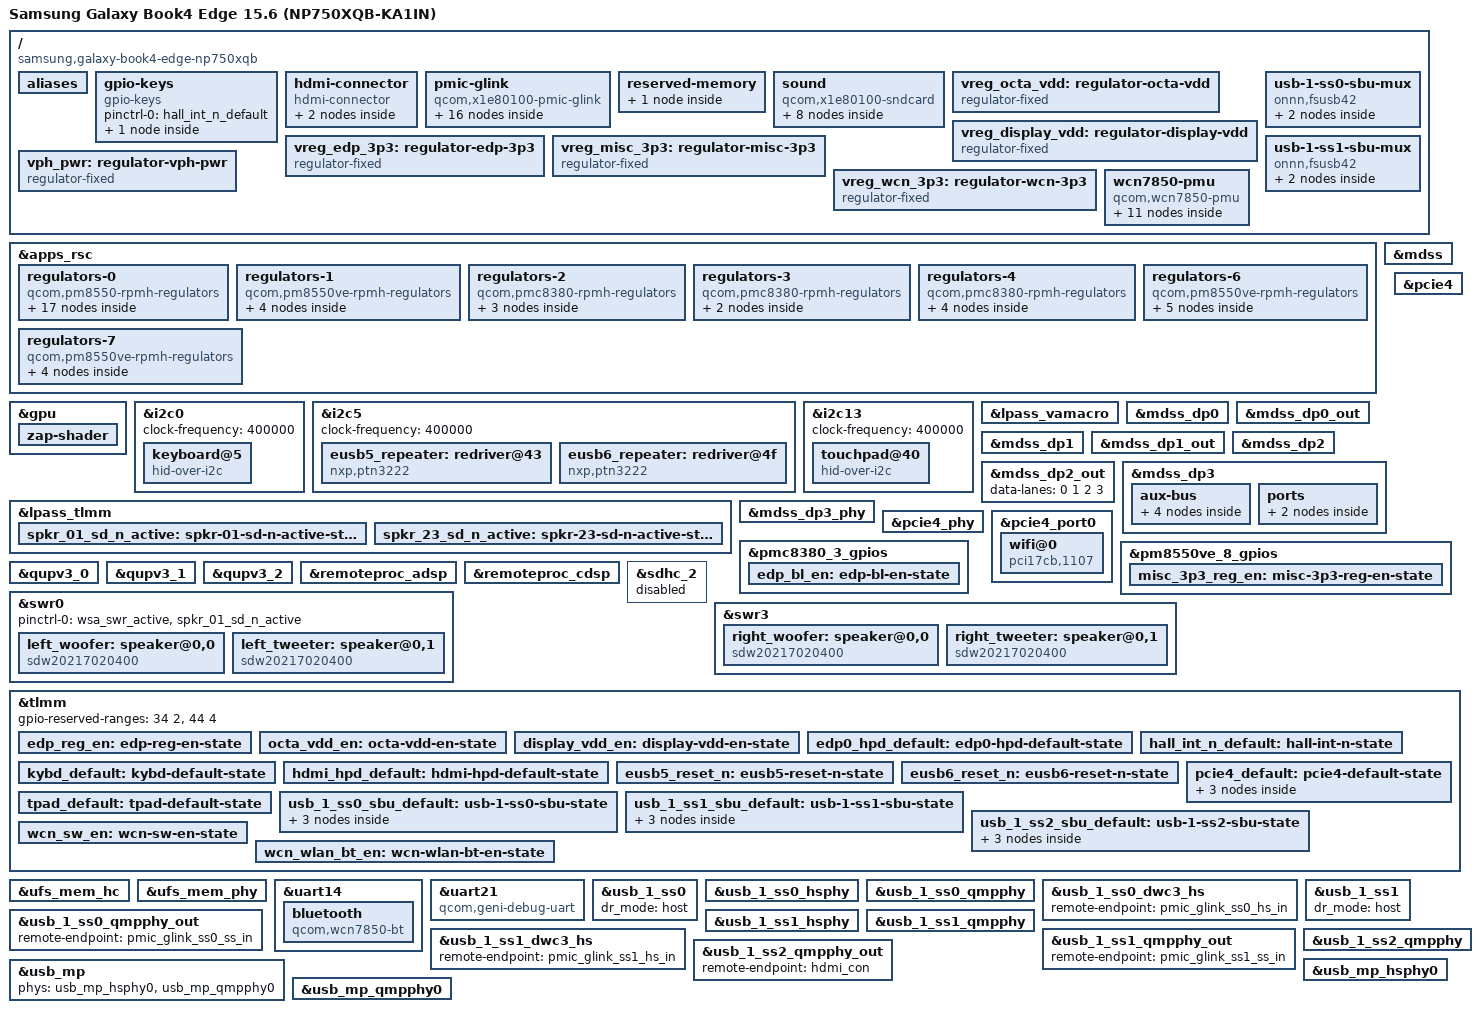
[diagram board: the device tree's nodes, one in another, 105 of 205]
// SPDX-License-Identifier: BSD-3-Clause
/*
 * Copyright (c) 2023 Qualcomm Innovation Center, Inc. All rights reserved.
 * Copyright (c) 2025 Kirill A. Korinsky <kirill@korins.ky>
 * Copyright (c) 2025 Valentin Manea <valentin.manea@mrs.ro>
 *
 * Rebased for the Samsung Galaxy Book4 Edge 15.6" (NP750XQB-KA1IN, India SKU),
 * which uses the Purwa die (X1P-26-100 marketing name) — the same silicon as
 * X1P-42-100 (purwa.dtsi) but clocked down 3.4GHz -> 3.0GHz, with 8 of 12 cores
 * fused (confirmed from MADT: 4 efficiency + 4 performance active, cluster 2
 * disabled). Board-level nodes below are carried over from the X1E80100 16"
 * Book4 Edge (zensanp/linux-book4-edge) since it's the same board family, and
 * adjusted against our own DSDT/EDID/Windows-PnP reverse engineering where the
 * two boards diverge (panel, keyboard, PMIC count, MicroSD, HDMI bridge, audio
 * codec). Nodes still needing verification are marked TODO.
 */

/dts-v1/;

#include <dt-bindings/gpio/gpio.h>
#include <dt-bindings/input/gpio-keys.h>
#include <dt-bindings/input/input.h>
#include <dt-bindings/pinctrl/qcom,pmic-gpio.h>
#include <dt-bindings/regulator/qcom,rpmh-regulator.h>

#include "purwa.dtsi"
#include "hamoa-pmics.dtsi"

/* Purwa is 5-PMIC (SIDS=SCP_PURWA); Hamoa/X1E is 6-PMIC.
 * purwa.dtsi should already omit pmc8380_6, but delete defensively
 * in case the included dtsi still carries it from the shared base.
 */
/delete-node/ &pmc8380_6;
/delete-node/ &pmc8380_6_thermal;

/ {
	model = "Samsung Galaxy Book4 Edge 15.6 (NP750XQB-KA1IN)";
	compatible = "samsung,galaxy-book4-edge-np750xqb", "qcom,x1p26100";
	chassis-type = "laptop";

	aliases {
		serial0 = &uart21;
		serial1 = &uart14;
	};

	/*
	 * TODO: NP750XQB uses a Samsung SAMM0851 custom WCD codec over
	 * SlimBus (per Windows PnP + DSDT), NOT the WCD9385 SoundWire codec
	 * this board template uses. No upstream driver/binding exists for
	 * SAMM0851 yet. Omitting the codec node (and its DAI links below)
	 * until that's reverse engineered further — audio will be silent
	 * until then.
	 */

	gpio-keys {
		compatible = "gpio-keys";

		pinctrl-0 = <&hall_int_n_default>;
		pinctrl-names = "default";

		switch-lid {
			gpios = <&tlmm 92 GPIO_ACTIVE_LOW>;
			linux,input-type = <EV_SW>;
			linux,code = <SW_LID>;
			wakeup-source;
			wakeup-event-action = <EV_ACT_DEASSERTED>;
		};
	};

	/*
	 * TODO: this wires HDMI straight off the DP QMP PHY (direct-connector
	 * model), same as the X1E board template. But our DSDT shows a
	 * parade,ps185hdm bridge IC in the signal path, which is a real DRM
	 * bridge device needing its own I2C node + driver, not a passive
	 * level shifter — the connector-only model below is probably wrong
	 * for this board. Left as-is (untested) until the bridge's I2C bus
	 * and address are identified.
	 */
	hdmi-connector {
		compatible = "hdmi-connector";
		type = "a";
		pinctrl-0 = <&hdmi_hpd_default>;
		pinctrl-names = "default";

		port {
			hdmi_con: endpoint {
				remote-endpoint = <&usb_1_ss2_qmpphy_out>;
			};
		};
	};

	pmic-glink {
		compatible = "qcom,x1e80100-pmic-glink",
			     "qcom,sm8550-pmic-glink",
			     "qcom,pmic-glink";
		#address-cells = <1>;
		#size-cells = <0>;
		orientation-gpios = <&tlmm 121 GPIO_ACTIVE_HIGH>,
				    <&tlmm 123 GPIO_ACTIVE_HIGH>,
				    <&tlmm 125 GPIO_ACTIVE_HIGH>;

		/* Left-side rear port */
		connector@0 {
			compatible = "usb-c-connector";
			reg = <0>;
			power-role = "dual";
			data-role = "dual";

			ports {
				#address-cells = <1>;
				#size-cells = <0>;

				port@0 {
					reg = <0>;

					pmic_glink_ss0_hs_in: endpoint {
						remote-endpoint = <&usb_1_ss0_dwc3_hs>;
					};
				};

				port@1 {
					reg = <1>;

					pmic_glink_ss0_ss_in: endpoint {
						remote-endpoint = <&usb_1_ss0_qmpphy_out>;
					};
				};

				port@2 {
					reg = <2>;

					pmic_glink_ss0_sbu: endpoint {
						remote-endpoint = <&usb_1_ss0_sbu_mux>;
					};
				};
			};
		};

		/* Left-side front port */
		connector@1 {
			compatible = "usb-c-connector";
			reg = <1>;
			power-role = "dual";
			data-role = "dual";

			ports {
				#address-cells = <1>;
				#size-cells = <0>;

				port@0 {
					reg = <0>;

					pmic_glink_ss1_hs_in: endpoint {
						remote-endpoint = <&usb_1_ss1_dwc3_hs>;
					};
				};

				port@1 {
					reg = <1>;

					pmic_glink_ss1_ss_in: endpoint {
						remote-endpoint = <&usb_1_ss1_qmpphy_out>;
					};
				};

				port@2 {
					reg = <2>;

					pmic_glink_ss1_sbu: endpoint {
						remote-endpoint = <&usb_1_ss1_sbu_mux>;
					};
				};
			};
		};
	};

	reserved-memory {
		linux,cma {
			compatible = "shared-dma-pool";
			size = <0x0 0x8000000>;
			reusable;
			linux,cma-default;
		};
	};

	sound {
		compatible = "qcom,x1e80100-sndcard";
		model = "X1E80100-CRD";
		audio-routing = "WooferLeft IN", "WSA WSA_SPK1 OUT",
				"TweeterLeft IN", "WSA WSA_SPK2 OUT",
				"WooferRight IN", "WSA2 WSA_SPK2 OUT",
				"TweeterRight IN", "WSA2 WSA_SPK2 OUT",
				"IN1_HPHL", "HPHL_OUT",
				"IN2_HPHR", "HPHR_OUT",
				"AMIC2", "MIC BIAS2",
				"VA DMIC0", "MIC BIAS3",
				"VA DMIC1", "MIC BIAS3",
				"VA DMIC2", "MIC BIAS1",
				"VA DMIC3", "MIC BIAS1",
				"VA DMIC0", "VA MIC BIAS3",
				"VA DMIC1", "VA MIC BIAS3",
				"VA DMIC2", "VA MIC BIAS1",
				"VA DMIC3", "VA MIC BIAS1",
				"TX SWR_INPUT1", "ADC2_OUTPUT";

		/*
		 * TODO: playback/capture through the headset codec path
		 * (WCD Playback / WCD Capture DAI links) removed here — they
		 * targeted &wcd938x, which doesn't exist on this board (see
		 * SAMM0851 TODO above). Speaker (WSA) and DMIC (VA) paths
		 * below don't depend on the headset codec and are kept.
		 */

		wsa-dai-link {
			link-name = "WSA Playback";

			cpu {
				sound-dai = <&q6apmbedai WSA_CODEC_DMA_RX_0>;
			};

			codec {
				sound-dai = <&left_woofer>, <&left_tweeter>,
					    <&swr0 0>, <&lpass_wsamacro 0>,
					    <&right_woofer>, <&right_tweeter>,
					    <&swr3 0>, <&lpass_wsa2macro 0>;
			};

			platform {
				sound-dai = <&q6apm>;
			};
		};

		va-dai-link {
			link-name = "VA Capture";

			cpu {
				sound-dai = <&q6apmbedai VA_CODEC_DMA_TX_0>;
			};

			codec {
				sound-dai = <&lpass_vamacro 0>;
			};

			platform {
				sound-dai = <&q6apm>;
			};
		};
	};

	vreg_octa_vdd: regulator-octa-vdd {
		compatible = "regulator-fixed";

		regulator-name = "VREG_OCTA_VDD";
		regulator-min-microvolt = <1800000>;
		regulator-max-microvolt = <1800000>;

		gpio = <&tlmm 111 GPIO_ACTIVE_HIGH>;
		enable-active-high;

		pinctrl-0 = <&octa_vdd_en>;
		pinctrl-names = "default";

		startup-delay-us = <1000>;
		regulator-enable-ramp-delay = <1000>;

		regulator-always-on;
		regulator-boot-on;
	};

	vreg_display_vdd: regulator-display-vdd {
		compatible = "regulator-fixed";

		regulator-name = "VREG_DISPLAY_VDD";
		regulator-min-microvolt = <3300000>;
		regulator-max-microvolt = <3300000>;

		gpio = <&tlmm 120 GPIO_ACTIVE_HIGH>;
		enable-active-high;

		pinctrl-0 = <&display_vdd_en>;
		pinctrl-names = "default";

		startup-delay-us = <400000>;
		regulator-enable-ramp-delay = <400000>;

		vin-supply = <&vreg_octa_vdd>;

		regulator-always-on;
		regulator-boot-on;
	};

	vreg_edp_3p3: regulator-edp-3p3 {
		compatible = "regulator-fixed";

		regulator-name = "VREG_EDP_3P3";
		regulator-min-microvolt = <3300000>;
		regulator-max-microvolt = <3300000>;

		gpio = <&tlmm 70 GPIO_ACTIVE_LOW>;
		enable-active-low;

		pinctrl-0 = <&edp_reg_en>;
		pinctrl-names = "default";

		startup-delay-us = <1000>;
		regulator-enable-ramp-delay = <1000>;

		vin-supply = <&vreg_display_vdd>;

		regulator-always-on;
		regulator-boot-on;
	};


	vreg_misc_3p3: regulator-misc-3p3 {
		compatible = "regulator-fixed";

		regulator-name = "VREG_MISC_3P3";
		regulator-min-microvolt = <3300000>;
		regulator-max-microvolt = <3300000>;

		gpio = <&pm8550ve_8_gpios 6 GPIO_ACTIVE_HIGH>;
		enable-active-high;

		pinctrl-names = "default";
		pinctrl-0 = <&misc_3p3_reg_en>;

		regulator-boot-on;
		regulator-always-on;
	};

	vph_pwr: regulator-vph-pwr {
		compatible = "regulator-fixed";

		regulator-name = "vph_pwr";
		regulator-min-microvolt = <3700000>;
		regulator-max-microvolt = <3700000>;

		regulator-always-on;
		regulator-boot-on;
	};

	vreg_wcn_3p3: regulator-wcn-3p3 {
		compatible = "regulator-fixed";

		regulator-name = "VREG_WCN_3P3";
		regulator-min-microvolt = <3300000>;
		regulator-max-microvolt = <3300000>;

		gpio = <&tlmm 214 GPIO_ACTIVE_HIGH>;
		enable-active-high;

		pinctrl-0 = <&wcn_sw_en>;
		pinctrl-names = "default";

		regulator-boot-on;
		regulator-always-on;
	};

	usb-1-ss0-sbu-mux {
		compatible = "onnn,fsusb42", "gpio-sbu-mux";

		enable-gpios = <&tlmm 168 GPIO_ACTIVE_LOW>;
		select-gpios = <&tlmm 167 GPIO_ACTIVE_HIGH>;

		pinctrl-0 = <&usb_1_ss0_sbu_default>;
		pinctrl-names = "default";

		mode-switch;
		orientation-switch;

		port {
			usb_1_ss0_sbu_mux: endpoint {
				remote-endpoint = <&pmic_glink_ss0_sbu>;
			};
		};
	};

	usb-1-ss1-sbu-mux {
		compatible = "onnn,fsusb42", "gpio-sbu-mux";

		enable-gpios = <&tlmm 179 GPIO_ACTIVE_LOW>;
		select-gpios = <&tlmm 178 GPIO_ACTIVE_HIGH>;

		pinctrl-0 = <&usb_1_ss1_sbu_default>;
		pinctrl-names = "default";

		mode-switch;
		orientation-switch;

		port {
			usb_1_ss1_sbu_mux: endpoint {
				remote-endpoint = <&pmic_glink_ss1_sbu>;
			};
		};
	};

	wcn7850-pmu {
		compatible = "qcom,wcn7850-pmu";

		wlan-enable-gpios = <&tlmm 117 GPIO_ACTIVE_HIGH>;
		bt-enable-gpios = <&tlmm 116 GPIO_ACTIVE_HIGH>;

		pinctrl-0 = <&wcn_wlan_bt_en>;
		pinctrl-names = "default";

		regulators {
			vreg_pmu_rfa_cmn: ldo0 {
				regulator-name = "vreg_pmu_rfa_cmn";
			};

			vreg_pmu_aon_0p59: ldo1 {
				regulator-name = "vreg_pmu_aon_0p59";
			};

			vreg_pmu_wlcx_0p8: ldo2 {
				regulator-name = "vreg_pmu_wlcx_0p8";
			};

			vreg_pmu_wlmx_0p85: ldo3 {
				regulator-name = "vreg_pmu_wlmx_0p85";
			};

			vreg_pmu_btcmx_0p85: ldo4 {
				regulator-name = "vreg_pmu_btcmx_0p85";
			};

			vreg_pmu_rfa_0p8: ldo5 {
				regulator-name = "vreg_pmu_rfa_0p8";
			};

			vreg_pmu_rfa_1p2: ldo6 {
				regulator-name = "vreg_pmu_rfa_1p2";
			};

			vreg_pmu_rfa_1p8: ldo7 {
				regulator-name = "vreg_pmu_rfa_1p8";
			};

			vreg_pmu_pcie_0p9: ldo8 {
				regulator-name = "vreg_pmu_pcie_0p9";
			};

			vreg_pmu_pcie_1p8: ldo9 {
				regulator-name = "vreg_pmu_pcie_1p8";
			};
		};
	};
};

&apps_rsc {
	regulators-0 {
		compatible = "qcom,pm8550-rpmh-regulators";
		qcom,pmic-id = "b";

		vdd-bob1-supply = <&vph_pwr>;
		vdd-bob2-supply = <&vph_pwr>;
		vdd-l1-l4-l10-supply = <&vreg_s4c_1p8>;
		vdd-l2-l13-l14-supply = <&vreg_bob1>;
		vdd-l5-l16-supply = <&vreg_bob1>;
		vdd-l6-l7-supply = <&vreg_bob2>;
		vdd-l8-l9-supply = <&vreg_bob1>;
		vdd-l12-supply = <&vreg_s5j_1p2>;
		vdd-l15-supply = <&vreg_s4c_1p8>;
		vdd-l17-supply = <&vreg_bob2>;

		vreg_bob1: bob1 {
			regulator-name = "vreg_bob1";
			regulator-min-microvolt = <3008000>;
			regulator-max-microvolt = <3960000>;
			regulator-initial-mode = <RPMH_REGULATOR_MODE_HPM>;
		};

		vreg_bob2: bob2 {
			regulator-name = "vreg_bob2";
			regulator-min-microvolt = <2504000>;
			regulator-max-microvolt = <3008000>;
			regulator-initial-mode = <RPMH_REGULATOR_MODE_HPM>;
		};

		vreg_l1b_1p8: ldo1 {
			regulator-name = "vreg_l1b_1p8";
			regulator-min-microvolt = <1800000>;
			regulator-max-microvolt = <1800000>;
			regulator-initial-mode = <RPMH_REGULATOR_MODE_HPM>;
		};

		vreg_l2b_3p0: ldo2 {
			regulator-name = "vreg_l2b_3p0";
			regulator-min-microvolt = <3072000>;
			regulator-max-microvolt = <3100000>;
			regulator-initial-mode = <RPMH_REGULATOR_MODE_HPM>;
		};

		vreg_l4b_1p8: ldo4 {
			regulator-name = "vreg_l4b_1p8";
			regulator-min-microvolt = <1800000>;
			regulator-max-microvolt = <1800000>;
			regulator-initial-mode = <RPMH_REGULATOR_MODE_HPM>;
		};

		vreg_l5b_3p0: ldo5 {
			regulator-name = "vreg_l5b_3p0";
			regulator-min-microvolt = <3000000>;
			regulator-max-microvolt = <3000000>;
			regulator-initial-mode = <RPMH_REGULATOR_MODE_HPM>;
		};

		vreg_l6b_1p8: ldo6 {
			regulator-name = "vreg_l6b_1p8";
			regulator-min-microvolt = <1800000>;
			regulator-max-microvolt = <2960000>;
			regulator-initial-mode = <RPMH_REGULATOR_MODE_HPM>;
		};

		vreg_l7b_2p8: ldo7 {
			regulator-name = "vreg_l7b_2p8";
			regulator-min-microvolt = <2800000>;
			regulator-max-microvolt = <2800000>;
			regulator-initial-mode = <RPMH_REGULATOR_MODE_HPM>;
		};

		vreg_l8b_3p0: ldo8 {
			regulator-name = "vreg_l8b_3p0";
			regulator-min-microvolt = <3072000>;
			regulator-max-microvolt = <3072000>;
			regulator-initial-mode = <RPMH_REGULATOR_MODE_HPM>;
		};

		vreg_l9b_2p9: ldo9 {
			regulator-name = "vreg_l9b_2p9";
			regulator-min-microvolt = <2960000>;
			regulator-max-microvolt = <2960000>;
			regulator-initial-mode = <RPMH_REGULATOR_MODE_HPM>;
		};

		vreg_l10b_1p8: ldo10 {
			regulator-name = "vreg_l10b_1p8";
			regulator-min-microvolt = <1800000>;
			regulator-max-microvolt = <1800000>;
			regulator-initial-mode = <RPMH_REGULATOR_MODE_HPM>;
		};

		vreg_l12b_1p2: ldo12 {
			regulator-name = "vreg_l12b_1p2";
			regulator-min-microvolt = <1200000>;
			regulator-max-microvolt = <1200000>;
			regulator-initial-mode = <RPMH_REGULATOR_MODE_HPM>;
			regulator-always-on;
		};

		vreg_l13b_3p0: ldo13 {
			regulator-name = "vreg_l13b_3p0";
			regulator-min-microvolt = <3072000>;
			regulator-max-microvolt = <3100000>;
			regulator-initial-mode = <RPMH_REGULATOR_MODE_HPM>;
		};

		vreg_l14b_3p0: ldo14 {
			regulator-name = "vreg_l14b_3p0";
			regulator-min-microvolt = <3072000>;
			regulator-max-microvolt = <3072000>;
			regulator-initial-mode = <RPMH_REGULATOR_MODE_HPM>;
		};

		vreg_l15b_1p8: ldo15 {
			regulator-name = "vreg_l15b_1p8";
			regulator-min-microvolt = <1800000>;
			regulator-max-microvolt = <1800000>;
			regulator-initial-mode = <RPMH_REGULATOR_MODE_HPM>;
			regulator-always-on;
		};

		vreg_l16b_2p9: ldo16 {
			regulator-name = "vreg_l16b_2p9";
			regulator-min-microvolt = <2912000>;
			regulator-max-microvolt = <2912000>;
			regulator-initial-mode = <RPMH_REGULATOR_MODE_HPM>;
		};

		vreg_l17b_2p5: ldo17 {
			regulator-name = "vreg_l17b_2p5";
			regulator-min-microvolt = <2504000>;
			regulator-max-microvolt = <2504000>;
			regulator-initial-mode = <RPMH_REGULATOR_MODE_HPM>;
		};
	};

	regulators-1 {
		compatible = "qcom,pm8550ve-rpmh-regulators";
		qcom,pmic-id = "c";

		vdd-l1-supply = <&vreg_s5j_1p2>;
		vdd-l2-supply = <&vreg_s1f_0p7>;
		vdd-l3-supply = <&vreg_s1f_0p7>;
		vdd-s4-supply = <&vph_pwr>;

		vreg_s4c_1p8: smps4 {
			regulator-name = "vreg_s4c_1p8";
			regulator-min-microvolt = <1856000>;
			regulator-max-microvolt = <2000000>;
			regulator-initial-mode = <RPMH_REGULATOR_MODE_HPM>;
		};

		vreg_l1c_1p2: ldo1 {
			regulator-name = "vreg_l1c_1p2";
			regulator-min-microvolt = <1200000>;
			regulator-max-microvolt = <1200000>;
			regulator-initial-mode = <RPMH_REGULATOR_MODE_HPM>;
		};

		vreg_l2c_0p8: ldo2 {
			regulator-name = "vreg_l2c_0p8";
			regulator-min-microvolt = <880000>;
			regulator-max-microvolt = <920000>;
			regulator-initial-mode = <RPMH_REGULATOR_MODE_HPM>;
		};

		vreg_l3c_0p8: ldo3 {
			regulator-name = "vreg_l3c_0p8";
			regulator-min-microvolt = <880000>;
			regulator-max-microvolt = <920000>;
			regulator-initial-mode = <RPMH_REGULATOR_MODE_HPM>;
		};
	};

	regulators-2 {
		compatible = "qcom,pmc8380-rpmh-regulators";
		qcom,pmic-id = "d";

		vdd-l1-supply = <&vreg_s1f_0p7>;
		vdd-l2-supply = <&vreg_s1f_0p7>;
		vdd-l3-supply = <&vreg_s4c_1p8>;
		vdd-s1-supply = <&vph_pwr>;

		vreg_l1d_0p8: ldo1 {
			regulator-name = "vreg_l1d_0p8";
			regulator-min-microvolt = <880000>;
			regulator-max-microvolt = <920000>;
			regulator-initial-mode = <RPMH_REGULATOR_MODE_HPM>;
		};

		vreg_l2d_0p9: ldo2 {
			regulator-name = "vreg_l2d_0p9";
			regulator-min-microvolt = <912000>;
			regulator-max-microvolt = <920000>;
			regulator-initial-mode = <RPMH_REGULATOR_MODE_HPM>;
		};

		vreg_l3d_1p8: ldo3 {
			regulator-name = "vreg_l3d_1p8";
			regulator-min-microvolt = <1800000>;
			regulator-max-microvolt = <1800000>;
			regulator-initial-mode = <RPMH_REGULATOR_MODE_HPM>;
		};
	};

	regulators-3 {
		compatible = "qcom,pmc8380-rpmh-regulators";
		qcom,pmic-id = "e";

		vdd-l2-supply = <&vreg_s1f_0p7>;
		vdd-l3-supply = <&vreg_s5j_1p2>;

		vreg_l2e_0p8: ldo2 {
			regulator-name = "vreg_l2e_0p8";
			regulator-min-microvolt = <880000>;
			regulator-max-microvolt = <920000>;
			regulator-initial-mode = <RPMH_REGULATOR_MODE_HPM>;
		};

		vreg_l3e_1p2: ldo3 {
			regulator-name = "vreg_l3e_1p2";
			regulator-min-microvolt = <1200000>;
			regulator-max-microvolt = <1200000>;
			regulator-initial-mode = <RPMH_REGULATOR_MODE_HPM>;
		};
	};

	regulators-4 {
		compatible = "qcom,pmc8380-rpmh-regulators";
		qcom,pmic-id = "f";

		vdd-l1-supply = <&vreg_s5j_1p2>;
		vdd-l2-supply = <&vreg_s5j_1p2>;
		vdd-l3-supply = <&vreg_s5j_1p2>;
		vdd-s1-supply = <&vph_pwr>;

		vreg_s1f_0p7: smps1 {
			regulator-name = "vreg_s1f_0p7";
			regulator-min-microvolt = <700000>;
			regulator-max-microvolt = <1100000>;
			regulator-initial-mode = <RPMH_REGULATOR_MODE_HPM>;
		};

		vreg_l1f_1p0: ldo1 {
			regulator-name = "vreg_l1f_1p0";
			regulator-min-microvolt = <1024000>;
			regulator-max-microvolt = <1024000>;
			regulator-initial-mode = <RPMH_REGULATOR_MODE_HPM>;
		};

		vreg_l2f_1p0: ldo2 {
			regulator-name = "vreg_l2f_1p0";
			regulator-min-microvolt = <1024000>;
			regulator-max-microvolt = <1024000>;
			regulator-initial-mode = <RPMH_REGULATOR_MODE_HPM>;
		};

		vreg_l3f_1p0: ldo3 {
			regulator-name = "vreg_l3f_1p0";
			regulator-min-microvolt = <1024000>;
			regulator-max-microvolt = <1024000>;
			regulator-initial-mode = <RPMH_REGULATOR_MODE_HPM>;
		};
	};

	regulators-6 {
		compatible = "qcom,pm8550ve-rpmh-regulators";
		qcom,pmic-id = "i";

		vdd-l1-supply = <&vreg_s4c_1p8>;
		vdd-l2-supply = <&vreg_s5j_1p2>;
		vdd-l3-supply = <&vreg_s1f_0p7>;
		vdd-s1-supply = <&vph_pwr>;
		vdd-s2-supply = <&vph_pwr>;

		vreg_s1i_0p9: smps1 {
			regulator-name = "vreg_s1i_0p9";
			regulator-min-microvolt = <900000>;
			regulator-max-microvolt = <920000>;
			regulator-initial-mode = <RPMH_REGULATOR_MODE_HPM>;
		};

		vreg_s2i_1p0: smps2 {
			regulator-name = "vreg_s2i_1p0";
			regulator-min-microvolt = <1000000>;
			regulator-max-microvolt = <1100000>;
			regulator-initial-mode = <RPMH_REGULATOR_MODE_HPM>;
		};

		vreg_l1i_1p8: ldo1 {
			regulator-name = "vreg_l1i_1p8";
			regulator-min-microvolt = <1800000>;
			regulator-max-microvolt = <1800000>;
			regulator-initial-mode = <RPMH_REGULATOR_MODE_HPM>;
		};

		vreg_l2i_1p2: ldo2 {
			regulator-name = "vreg_l2i_1p2";
			regulator-min-microvolt = <1200000>;
			regulator-max-microvolt = <1200000>;
			regulator-initial-mode = <RPMH_REGULATOR_MODE_HPM>;
		};

		vreg_l3i_0p8: ldo3 {
			regulator-name = "vreg_l3i_0p8";
			regulator-min-microvolt = <880000>;
			regulator-max-microvolt = <920000>;
			regulator-initial-mode = <RPMH_REGULATOR_MODE_HPM>;
		};
	};

	regulators-7 {
		compatible = "qcom,pm8550ve-rpmh-regulators";
		qcom,pmic-id = "j";

		vdd-l1-supply = <&vreg_s1f_0p7>;
		vdd-l2-supply = <&vreg_s5j_1p2>;
		vdd-l3-supply = <&vreg_s1f_0p7>;
		vdd-s5-supply = <&vph_pwr>;

		vreg_s5j_1p2: smps5 {
			regulator-name = "vreg_s5j_1p2";
			regulator-min-microvolt = <1256000>;
			regulator-max-microvolt = <1304000>;
			regulator-initial-mode = <RPMH_REGULATOR_MODE_HPM>;
		};

		vreg_l1j_0p8: ldo1 {
			regulator-name = "vreg_l1j_0p8";
			regulator-min-microvolt = <880000>;
			regulator-max-microvolt = <920000>;
			regulator-initial-mode = <RPMH_REGULATOR_MODE_HPM>;
		};

		vreg_l2j_1p2: ldo2 {
			regulator-name = "vreg_l2j_1p2";
			regulator-min-microvolt = <1256000>;
			regulator-max-microvolt = <1256000>;
			regulator-initial-mode = <RPMH_REGULATOR_MODE_HPM>;
		};

		vreg_l3j_0p8: ldo3 {
			regulator-name = "vreg_l3j_0p8";
			regulator-min-microvolt = <880000>;
			regulator-max-microvolt = <920000>;
			regulator-initial-mode = <RPMH_REGULATOR_MODE_HPM>;
		};
	};
};

&gpu {
       status = "okay";

       zap-shader {
               /* Purwa-specific zap shader, confirmed from Windows DriverStore */
               firmware-name = "qcom/x1p26100/SAMSUNG/NP750XQB/qcdxkmsucpurwa.mbn";
       };
};

&i2c0 {
	clock-frequency = <400000>;

	status = "okay";

	/*
	 * Matches our own reverse-engineered SSEC0001 keyboard exactly on
	 * every attribute (addr 0x05, hid-descr-addr 0x20, IRQ on gpio67) —
	 * strong confirmation. One label mismatch to reconcile: our earlier
	 * ACPI-derived notes called this bus "i2c5", this board template
	 * calls it "i2c0". Likely just a QUP-instance-vs-alias naming
	 * difference rather than a real conflict, but verify the qupv3 i2c0
	 * alias actually maps to the same QUP block before trusting this.
	 */
	keyboard@5 {
		compatible = "hid-over-i2c";
		reg = <0x5>;

		hid-descr-addr = <0x20>;
		interrupts-extended = <&tlmm 67 IRQ_TYPE_LEVEL_LOW>;

		pinctrl-0 = <&kybd_default>;
		pinctrl-names = "default";

		wakeup-source;
	};
};

&i2c5 {
	clock-frequency = <400000>;

	status = "okay";

	eusb5_repeater: redriver@43 {
		compatible = "nxp,ptn3222";
		reg = <0x43>;
		#phy-cells = <0>;

		vdd3v3-supply = <&vreg_l13b_3p0>;
		vdd1v8-supply = <&vreg_l4b_1p8>;

		reset-gpios = <&tlmm 7 GPIO_ACTIVE_LOW>;

		pinctrl-0 = <&eusb5_reset_n>;
		pinctrl-names = "default";
	};

	eusb6_repeater: redriver@4f {
		compatible = "nxp,ptn3222";
		reg = <0x4f>;
		#phy-cells = <0>;

		vdd3v3-supply = <&vreg_l13b_3p0>;
		vdd1v8-supply = <&vreg_l4b_1p8>;

		reset-gpios = <&tlmm 184 GPIO_ACTIVE_LOW>;

		pinctrl-0 = <&eusb6_reset_n>;
		pinctrl-names = "default";
	};
};


/*
 * NP750XQB-KA1IN is a non-touch panel variant — no touchscreen on i2c8.
 * (X1E 16" board template had one at 0x5d; omitted here.)
 */

&i2c13 {
	clock-frequency = <400000>;

	status = "okay";

	touchpad@40 {
		compatible = "hid-over-i2c";
		reg = <0x40>;

		hid-descr-addr = <0xe>;
		interrupts-extended = <&tlmm 3 IRQ_TYPE_LEVEL_LOW>;

		pinctrl-0 = <&tpad_default>;
		pinctrl-names = "default";
	};
};

&lpass_tlmm {
	spkr_01_sd_n_active: spkr-01-sd-n-active-state {
		pins = "gpio12";
		function = "gpio";
		drive-strength = <16>;
		bias-disable;
		output-low;
	};

	spkr_23_sd_n_active: spkr-23-sd-n-active-state {
		pins = "gpio13";
		function = "gpio";
		drive-strength = <16>;
		bias-disable;
		output-low;
	};
};

&lpass_vamacro {
	pinctrl-0 = <&dmic01_default>, <&dmic23_default>;
	pinctrl-names = "default";

	vdd-micb-supply = <&vreg_l1b_1p8>;
	qcom,dmic-sample-rate = <4800000>;
};

&mdss {
	status = "okay";
};

&mdss_dp0 {
	status = "okay";
};

&mdss_dp0_out {
	data-lanes = <0 1>;
	link-frequencies = /bits/ 64 <1620000000 2700000000 5400000000 8100000000>;
};

&mdss_dp1 {
	status = "okay";
};

&mdss_dp1_out {
	data-lanes = <0 1>;
	link-frequencies = /bits/ 64 <1620000000 2700000000 5400000000 8100000000>;
};

&mdss_dp2 {
	status = "okay";
};

&mdss_dp2_out {
	data-lanes = <0 1 2 3>;
};

&mdss_dp3 {
	/delete-property/ #sound-dai-cells;

	pinctrl-0 = <&edp0_hpd_default>;
	pinctrl-names = "default";

	status = "okay";
	no-hpd;

	aux-bus {
		panel {
			/*
			 * NP750XQB ships a 1920x1080 60Hz BOE IPS panel
			 * (NV156FHM-NS0, product code 0x0BF0, Windows
			 * DISPLAY\BOE0BF0) — not the 3K AMOLED atna60cl07
			 * this board template targets. No upstream DT
			 * binding exists for it yet, so this falls back to
			 * the generic edp-panel binding with EDID-decoded
			 * timings (147.31MHz pixel clock).
			 * TODO: upstream a proper boe,nv156fhm-ns0 binding.
			 */
			compatible = "edp-panel";
			enable-gpios = <&pmc8380_3_gpios 4 GPIO_ACTIVE_HIGH>;
			power-supply = <&vreg_edp_3p3>;
			no-hpd;

			pinctrl-0 = <&edp_bl_en>;
			pinctrl-names = "default";
            panel-width-mm = <344>;
            panel-height-mm = <194>;

			panel-timing {
				clock-frequency = <147310000>;
				hactive = <1920>;
				vactive = <1080>;
				hfront-porch = <48>;
				hsync-len = <32>;
				hback-porch = <192>;
				vfront-porch = <3>;
				vsync-len = <6>;
				vback-porch = <31>;
				hsync-active = <1>;
				vsync-active = <0>;
			};

			port {
				edp_panel_in: endpoint {
					remote-endpoint = <&mdss_dp3_out>;
				};
			};
		};
	};

	ports {
		port@1 {
			reg = <1>;
			mdss_dp3_out: endpoint {
				/* FHD panel — 2 lanes, no need for the AMOLED's 4-lane/5.4G config */
				data-lanes = <0 1>;
				link-frequencies = /bits/ 64 <1620000000 2700000000>;

				remote-endpoint = <&edp_panel_in>;
			};
		};
	};
};


&mdss_dp3_phy {
	vdda-phy-supply = <&vreg_l3j_0p8>;
	vdda-pll-supply = <&vreg_l2j_1p2>;

	status = "okay";
};

&pcie4 {
	perst-gpios = <&tlmm 146 GPIO_ACTIVE_LOW>;
	wake-gpios = <&tlmm 148 GPIO_ACTIVE_LOW>;

	pinctrl-0 = <&pcie4_default>;
	pinctrl-names = "default";

	status = "okay";
};

&pcie4_phy {
	vdda-phy-supply = <&vreg_l3i_0p8>;
	vdda-pll-supply = <&vreg_l3e_1p2>;

	status = "okay";
};

&pcie4_port0 {
	wifi@0 {
		compatible = "pci17cb,1107";
		reg = <0x10000 0x0 0x0 0x0 0x0>;

		vddaon-supply = <&vreg_pmu_aon_0p59>;
		vddwlcx-supply = <&vreg_pmu_wlcx_0p8>;
		vddwlmx-supply = <&vreg_pmu_wlmx_0p85>;
		vddrfacmn-supply = <&vreg_pmu_rfa_cmn>;
		vddrfa0p8-supply = <&vreg_pmu_rfa_0p8>;
		vddrfa1p2-supply = <&vreg_pmu_rfa_1p2>;
		vddrfa1p8-supply = <&vreg_pmu_rfa_1p8>;
		vddpcie0p9-supply = <&vreg_pmu_pcie_0p9>;
		vddpcie1p8-supply = <&vreg_pmu_pcie_1p8>;
	};
};

&pm8550ve_8_gpios {
	misc_3p3_reg_en: misc-3p3-reg-en-state {
		pins = "gpio6";
		function = "normal";
		bias-disable;
		input-disable;
		output-enable;
		drive-push-pull;
		power-source = <1>; /* 1.8 V */
		qcom,drive-strength = <PMIC_GPIO_STRENGTH_LOW>;
	};
};

&pmc8380_3_gpios {
	edp_bl_en: edp-bl-en-state {
		pins = "gpio4";
		function = "normal";
		power-source = <1>; /* 1.8V */
		input-disable;
		output-enable;
	};
};

&qupv3_0 {
	status = "okay";
};

&qupv3_1 {
	status = "okay";
};

&qupv3_2 {
	status = "okay";
};

&remoteproc_adsp {
	firmware-name = "qcom/x1p26100/SAMSUNG/NP750XQB/qcadsp8380.mbn",
			"qcom/x1p26100/SAMSUNG/NP750XQB/adsp_dtbs.elf";

	status = "okay";
};

&remoteproc_cdsp {
	firmware-name = "qcom/x1p26100/SAMSUNG/NP750XQB/qccdsp8380.mbn",
			"qcom/x1p26100/SAMSUNG/NP750XQB/cdsp_dtbs.elf";

	status = "okay";
};

&sdhc_2 {
	/*
	 * MicroSD slot on the right side (confirmed from Samsung spec page).
	 * Left DISABLED: pinctrl (sd_default/sd_sleep in &tlmm above) and
	 * cd-gpios both need the real GPIO numbers pulled from the DSDT
	 * SDHC_2 device's _CRS block — our earlier gpio48 guess for cd-gpios
	 * collides with the X1E board's touchscreen reset pin and should be
	 * treated as unreliable now (see &tlmm note above).
	 */
	status = "disabled";

	vmmc-supply = <&vreg_l9b_2p9>;
	vqmmc-supply = <&vreg_l6b_1p8>;

	bus-width = <4>;
	no-sdio;
	no-mmc;
	/* cd-gpios = <&tlmm ?? GPIO_ACTIVE_LOW>; TODO */
};

&swr0 {
	status = "okay";

	pinctrl-0 = <&wsa_swr_active>, <&spkr_01_sd_n_active>;
	pinctrl-names = "default";

	/* WSA8845, Left Woofer */
	left_woofer: speaker@0,0 {
		compatible = "sdw20217020400";
		reg = <0 0>;
		reset-gpios = <&lpass_tlmm 12 GPIO_ACTIVE_LOW>;
		#sound-dai-cells = <0>;
		sound-name-prefix = "WooferLeft";
		vdd-1p8-supply = <&vreg_l15b_1p8>;
		vdd-io-supply = <&vreg_l12b_1p2>;
		qcom,port-mapping = <1 2 3 7 10 13>;
	};

	/* WSA8845, Left Tweeter */
	left_tweeter: speaker@0,1 {
		compatible = "sdw20217020400";
		reg = <0 1>;
		reset-gpios = <&lpass_tlmm 12 GPIO_ACTIVE_LOW>;
		#sound-dai-cells = <0>;
		sound-name-prefix = "TweeterLeft";
		vdd-1p8-supply = <&vreg_l15b_1p8>;
		vdd-io-supply = <&vreg_l12b_1p2>;
		qcom,port-mapping = <4 5 6 7 11 13>;
	};
};

/*
 * TODO: swr1 (RX) and swr2 (TX) carried the WCD9385 headset codec on the
 * X1E board. NP750XQB's SAMM0851 codec is on SlimBus, not SoundWire, so
 * these buses likely have no child device here — leaving both disabled
 * until SlimBus enumeration is confirmed on first boot.
 */

&swr3 {
	status = "okay";

	pinctrl-0 = <&wsa2_swr_active>, <&spkr_23_sd_n_active>;
	pinctrl-names = "default";

	/* WSA8845, Right Woofer */
	right_woofer: speaker@0,0 {
		compatible = "sdw20217020400";
		reg = <0 0>;
		reset-gpios = <&lpass_tlmm 13 GPIO_ACTIVE_LOW>;
		#sound-dai-cells = <0>;
		sound-name-prefix = "WooferRight";
		vdd-1p8-supply = <&vreg_l15b_1p8>;
		vdd-io-supply = <&vreg_l12b_1p2>;
		qcom,port-mapping = <1 2 3 7 10 13>;
	};

	/* WSA8845, Right Tweeter */
	right_tweeter: speaker@0,1 {
		compatible = "sdw20217020400";
		reg = <0 1>;
		reset-gpios = <&lpass_tlmm 13 GPIO_ACTIVE_LOW>;
		#sound-dai-cells = <0>;
		sound-name-prefix = "TweeterRight";
		vdd-1p8-supply = <&vreg_l15b_1p8>;
		vdd-io-supply = <&vreg_l12b_1p2>;
		qcom,port-mapping = <4 5 6 7 11 13>;
	};
};

&tlmm {
	gpio-reserved-ranges = <34 2>, /* Unused */
			       <44 4>; /* SPI (TPM) */

	/*
	 * TODO: sd_default / sd_sleep (sdc2 clk/cmd/data pinctrl) not written
	 * yet — the real GPIOs need extracting from the DSDT SDHC_2 device's
	 * _CRS block first. &sdhc_2 below is left status = "disabled" and
	 * without pinctrl-0/1 references until that's done; do not add fake
	 * pin names here, dtc will reject unresolved pin names at build time.
	 */

	edp_reg_en: edp-reg-en-state {
		pins = "gpio70";
		function = "gpio";
		drive-strength = <16>;
		bias-pull-up;
		output-low;
	};

	octa_vdd_en: octa-vdd-en-state {
		pins = "gpio111";
		function = "gpio";
		drive-strength = <16>;
		bias-pull-up;
		output-high;
	};

	display_vdd_en: display-vdd-en-state {
		pins = "gpio120";
		function = "gpio";
		drive-strength = <16>;
		bias-pull-up;
		output-high;
	};

	edp0_hpd_default: edp0-hpd-default-state {
		pins = "gpio119";
		function = "edp0_hot";
		bias-pull-down;
		input-enable;
		drive-strength = <2>;
	};


	hall_int_n_default: hall-int-n-state {
		pins = "gpio92";
		function = "gpio";
		bias-disable;
	};

	kybd_default: kybd-default-state {
		pins = "gpio67";
		function = "gpio";
		bias-disable;
	};

	hdmi_hpd_default: hdmi-hpd-default-state {
		pins = "gpio126";
		function = "usb2_dp";
		bias-disable;
	};

	eusb5_reset_n: eusb5-reset-n-state {
		pins = "gpio7";
		function = "gpio";
		drive-strength = <2>;
		bias-disable;
		output-low;
	};

	eusb6_reset_n: eusb6-reset-n-state {
		pins = "gpio184";
		function = "gpio";
		drive-strength = <2>;
		bias-disable;
		output-low;
	};

	pcie4_default: pcie4-default-state {
		clkreq-n-pins {
			pins = "gpio147";
			function = "pcie4_clk";
			drive-strength = <2>;
			bias-pull-up;
		};

		perst-n-pins {
			pins = "gpio146";
			function = "gpio";
			drive-strength = <2>;
			bias-disable;
		};

		wake-n-pins {
			pins = "gpio148";
			function = "gpio";
			drive-strength = <2>;
			bias-pull-up;
		};
	};

	tpad_default: tpad-default-state {
		pins = "gpio3";
		function = "gpio";
		bias-disable;
	};

	/*
	 * ts0_default (touchscreen int-n/reset-n on gpio51/gpio48) removed —
	 * no touchscreen on this board (see i2c8 note above).
	 * NOTE: this board used gpio48 as the touchscreen reset line, which
	 * conflicts with our previous *tentative* guess of gpio48 for the
	 * MicroSD cd-gpios. That guess was carried over from the Vivobook
	 * reference and was never confirmed — treat it as more likely wrong
	 * now and re-derive the real MicroSD card-detect GPIO from the DSDT
	 * SDHC_2 resource block before relying on it.
	 */

	usb_1_ss0_sbu_default: usb-1-ss0-sbu-state {
		mode-pins {
			pins = "gpio166";
			function = "gpio";
			bias-disable;
			drive-strength = <2>;
			output-high;
		};

		oe-n-pins {
			pins = "gpio168";
			function = "gpio";
			bias-disable;
			drive-strength = <2>;
		};

		sel-pins {
			pins = "gpio167";
			function = "gpio";
			bias-disable;
			drive-strength = <2>;
		};

	};

	usb_1_ss1_sbu_default: usb-1-ss1-sbu-state {
		mode-pins {
			pins = "gpio177";
			function = "gpio";
			bias-disable;
			drive-strength = <2>;
			output-high;
		};

		oe-n-pins {
			pins = "gpio179";
			function = "gpio";
			bias-disable;
			drive-strength = <2>;
		};

		sel-pins {
			pins = "gpio178";
			function = "gpio";
			bias-disable;
			drive-strength = <2>;
		};
	};

	usb_1_ss2_sbu_default: usb-1-ss2-sbu-state {
		mode-pins {
			pins = "gpio169";
			function = "gpio";
			bias-disable;
			drive-strength = <2>;
			output-high;
		};

		oe-n-pins {
			pins = "gpio171";
			function = "gpio";
			bias-disable;
			drive-strength = <2>;
		};

		sel-pins {
			pins = "gpio170";
			function = "gpio";
			bias-disable;
			drive-strength = <2>;
		};
	};

	wcn_sw_en: wcn-sw-en-state {
		pins = "gpio214";
		function = "gpio";
		drive-strength = <2>;
		bias-disable;
	};

	wcn_wlan_bt_en: wcn-wlan-bt-en-state {
		pins = "gpio116", "gpio117";
		function = "gpio";
		drive-strength = <2>;
		bias-disable;
	};

	/* wcd-reset-n-active-state (gpio191) removed — was only used by the
	 * WCD9385 codec node, which doesn't apply here. TODO: gpio191 may
	 * still be the SAMM0851 reset line; verify before reassigning it.
	 */
};

&ufs_mem_hc {
	status = "okay";

	reset-gpios = <&tlmm 238 GPIO_ACTIVE_LOW>;
	vcc-supply = <&vreg_l17b_2p5>;
	vcc-max-microamp = <600000>;

	vccq-supply = <&vreg_l2i_1p2>;
	vccq-max-microamp = <600000>;
};

&ufs_mem_phy {
	status = "okay";

	vdda-phy-supply = <&vreg_l3i_0p8>;
	vdda-pll-supply = <&vreg_l3e_1p2>;
};

&uart14 {
	status = "okay";

	bluetooth {
		compatible = "qcom,wcn7850-bt";
		max-speed = <3200000>;

		vddaon-supply = <&vreg_pmu_aon_0p59>;
		vddwlcx-supply = <&vreg_pmu_wlcx_0p8>;
		vddwlmx-supply = <&vreg_pmu_wlmx_0p85>;
		vddrfacmn-supply = <&vreg_pmu_rfa_cmn>;
		vddrfa0p8-supply = <&vreg_pmu_rfa_0p8>;
		vddrfa1p2-supply = <&vreg_pmu_rfa_1p2>;
		vddrfa1p8-supply = <&vreg_pmu_rfa_1p8>;
	};
};

&uart21 {
	compatible = "qcom,geni-debug-uart";
	status = "okay";
};

/* usb1 covers left side typec ports */

/* back(towards the display) typec port */
&usb_1_ss0 {
	status = "okay";
};

&usb_1_ss0_hsphy {
	vdd-supply = <&vreg_l3j_0p8>;
	vdda12-supply = <&vreg_l2j_1p2>;

	status = "okay";
};

&usb_1_ss0_qmpphy {
	vdda-phy-supply = <&vreg_l2j_1p2>;
	vdda-pll-supply = <&vreg_l1j_0p8>;

	status = "okay";
};

&usb_1_ss0 {
	dr_mode = "host";
};

&usb_1_ss0_dwc3_hs {
	remote-endpoint = <&pmic_glink_ss0_hs_in>;
};

&usb_1_ss0_qmpphy_out {
	remote-endpoint = <&pmic_glink_ss0_ss_in>;
};

/* front typec port */
&usb_1_ss1 {
	status = "okay";
};

&usb_1_ss1_hsphy {
	vdd-supply = <&vreg_l3j_0p8>;
	vdda12-supply = <&vreg_l2j_1p2>;

	status = "okay";
};

&usb_1_ss1_qmpphy {
	vdda-phy-supply = <&vreg_l2j_1p2>;
	vdda-pll-supply = <&vreg_l2d_0p9>;

	status = "okay";
};

&usb_1_ss1 {
	dr_mode = "host";
};

&usb_1_ss1_dwc3_hs {
	remote-endpoint = <&pmic_glink_ss1_hs_in>;
};

&usb_1_ss1_qmpphy_out {
	remote-endpoint = <&pmic_glink_ss1_ss_in>;
};

/* DP-HDMI bridge connected here? */
&usb_1_ss2_qmpphy {
	vdda-phy-supply = <&vreg_l2j_1p2>;
	vdda-pll-supply = <&vreg_l2d_0p9>;

	qcom,combo-initial-mode = "dp";

	/delete-property/ mode-switch;
	/delete-property/ orientation-switch;

	status = "okay";
};

&usb_1_ss2_qmpphy_out {
	remote-endpoint = <&hdmi_con>;
};


/* MP0 goes to the USB-A port(USB3) and FPC */
&usb_mp {
	status = "okay";

	/* Limit to single port */
	phys = <&usb_mp_hsphy0>, <&usb_mp_qmpphy0>;
	phy-names = "usb2-0", "usb3-0";
};

&usb_mp_hsphy0 {
	vdd-supply = <&vreg_l2e_0p8>;
	vdda12-supply = <&vreg_l3e_1p2>;

	phys = <&eusb6_repeater>;

	status = "okay";
};

&usb_mp_qmpphy0 {
	vdda-phy-supply = <&vreg_l3e_1p2>;
	vdda-pll-supply = <&vreg_l3c_0p8>;

	status = "okay";
};
